# CONTROLSS_INTXBAR_CONTROLSS_INTXBAR register map
Vendor: Texas Instruments
Peripheral module from a debugger description file (folder AM263).
Registers are 16-bit, read-write, reset 0x0 unless marked. A register's access mark holds for its fields unless they carry their own. Offsets are as the file gives them; lines under a group give offsets from that group; [hi:lo] are bit positions; {n}, {i} and the like mark numbered series; 'fields as' and 'values as' point back to an identical list; <NAME> marks a mode.

## CONTROLSS_INTXBAR_CONTROLSS_INTXBAR
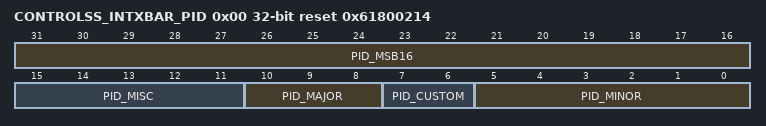
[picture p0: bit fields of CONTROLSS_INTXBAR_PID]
0x00 CONTROLSS_INTXBAR_PID 32-bit ro reset 0x61800214
  [31:16] PID_MSB16 — Not Defined
  [15:11] PID_MISC — Not Defined
  [10:8] PID_MAJOR — Not Defined
  [7:6] PID_CUSTOM — Not Defined
  [5:0] PID_MINOR — Not Defined
{0x100+0x40*i} CONTROLSS_INTXBAR_INTXBAR{i}_G0 32-bit (i=0..31)
  [31:0] SEL — ETPWM INT interrupt to corresponding xbar1: PWMx.INT is selected0: PWMx.INT is de-selected
{0x104+0x40*i} CONTROLSS_INTXBAR_INTXBAR{i}_G1 32-bit (i=0..31)
  [31:0] SEL — ETPWM TZINT interrupt to corresponding xbar1: PWMx.TZINT is selected0: PWMx.TZINT is de-selected
{0x108+0x40*i} CONTROLSS_INTXBAR_INTXBAR{i}_G2 24-bit (i=0..31)
  [24:0] SEL — Corresponding INT XBar G2 Input Select0: ADC0.INT11: ADC0.INT22: ADC0.INT33: ADC0.INT44: ADC0.EVTINT5: ADC1.INT16: ADC1.INT27: ADC1.INT38: ADC1.INT49: ADC1.EVTINT10: ADC2.INT111: ADC2.INT212: ADC2.INT313: ADC2.INT414: ADC2.EVTINT15: ADC3.INT116: ADC3.INT217: ADC3.INT318: ADC3.INT419: ADC3.EVTINT20: ADC4.INT121: ADC4.INT222: ADC4.INT323: ADC4.INT424: ADC4.EVTINT
{0x10C+0x40*i} CONTROLSS_INTXBAR_INTXBAR{i}_G3 (i=0..31)
  [15:0] SEL — Corresponding INT XBar G3 Input Select0: FSIRX0.INT1N1: FSIRX0.INT2N2: FSIRX1.INT1N3: FSIRX1.INT2N4: FSIRX2.INT1N5: FSIRX2.INT2N6: FSIRX3.INT1N7: FSIRX3.INT2N8: FSITX0.INT1N9: FSITX0.INT2N10: FSITX1.INT1N11: FSITX1.INT2N12: FSITX2.INT1N13: FSITX2.INT2N14: FSITX3.INT1N15: FSITX3.INT2N
{0x110+0x40*i} CONTROLSS_INTXBAR_INTXBAR{i}_G4 (i=0..31)
  [9:0] SEL — Corresponding INT XBar G4 Input Select0: SD0.ERR1: SD0.FILT1.DRINT2: SD0.FILT2.DRINT3: SD0.FILT3.DRINT4: SD0.FILT4.DRINT5: SD1.ERR6: SD1.FILT1.DRINT7: SD1.FILT2.DRINT8: SD1.FILT3.DRINT9: SD1.FILT4.DRINT
{0x114+0x40*i} CONTROLSS_INTXBAR_INTXBAR{i}_G5 (i=0..31)
  [9:0] SEL — Corresponding INT XBar G5 Input Select0: ECAP0.INT1: ECAP1.INT2: ECAP2.INT3: ECAP3.INT4: ECAP4.INT5: ECAP5.INT6: ECAP6.INT7: ECAP7.INT8: ECAP8.INT9: ECAP9.INT
{0x118+0x40*i} CONTROLSS_INTXBAR_INTXBAR{i}_G6 8-bit (i=0..31)
  [2:0] SEL — Corresponding INT XBar G6 Input Select0: EQEP0.INT1: EQEP1.INT2: EQEP2.INT
